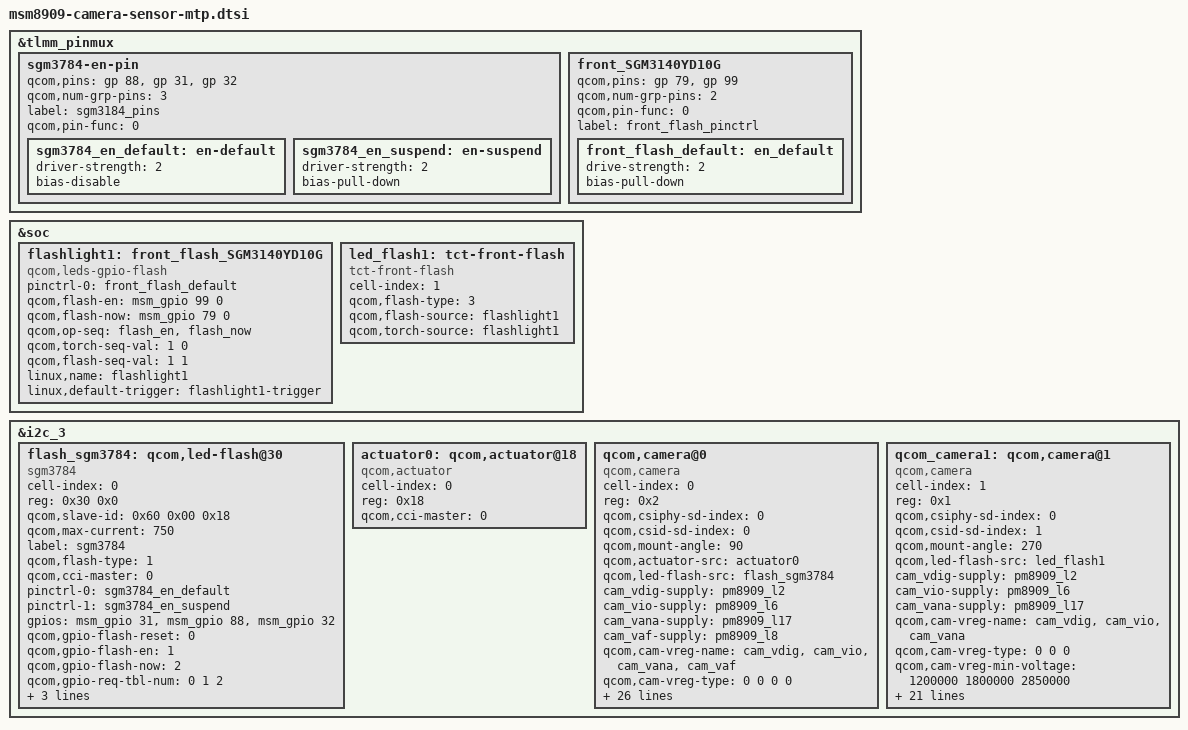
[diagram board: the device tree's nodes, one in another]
/*
 * Copyright (c) 2014-2015, The Linux Foundation. All rights reserved.
 *
 * This program is free software; you can redistribute it and/or modify
 * it under the terms of the GNU General Public License version 2 and
 * only version 2 as published by the Free Software Foundation.
 *
 * This program is distributed in the hope that it will be useful,
 * but WITHOUT ANY WARRANTY; without even the implied warranty of
 * MERCHANTABILITY or FITNESS FOR A PARTICULAR PURPOSE.  See the
 * GNU General Public License for more details.
 */
/*******************************************************************************

ChageList:

1.flashlight driver porting, by zhaohong.chen@tcl.com, 2016-01-18

*******************************************************************************/

&tlmm_pinmux {

	sgm3784-en-pin {
		qcom,pins = <&gp 88>, <&gp 31>, <&gp 32>;
		qcom,num-grp-pins = <3>;
		label = "sgm3184_pins";
		qcom,pin-func = <0>;

		sgm3784_en_default: en-default {
			driver-strength = <2>;
			bias-disable;
		};
		sgm3784_en_suspend: en-suspend {
			driver-strength = <2>;
			bias-pull-down;
		};
	};

	front_SGM3140YD10G {
		qcom,pins = <&gp 79>, <&gp 99>;
		qcom,num-grp-pins = <2>;
		qcom,pin-func = <0>;
		label = "front_flash_pinctrl";
		front_flash_default:en_default {
		drive-strength = <2>;
		bias-pull-down;
        };
    };
};

&soc {
	flashlight1:front_flash_SGM3140YD10G {
		compatible = "qcom,leds-gpio-flash";
		status = "okay";
		pinctrl-names = "flash_default";
		pinctrl-0 = <&front_flash_default>;
		qcom,flash-en = <&msm_gpio 99 0>;
		qcom,flash-now = <&msm_gpio 79 0>;
		qcom,op-seq = "flash_en", "flash_now";
		qcom,torch-seq-val = <1 0>;
		qcom,flash-seq-val = <1 1>;
		linux,name = "flashlight1";
		linux,default-trigger = "flashlight1-trigger";
	};

	led_flash1:tct-front-flash {
		cell-index = <1>;//front
		compatible = "tct-front-flash";
		qcom,flash-type = <3>;
		qcom,flash-source = <&flashlight1>;
		qcom,torch-source = <&flashlight1>;
	};
};

&i2c_3 {
	flash_sgm3784:qcom,led-flash@30 {
		cell-index = <0>;
		reg = <0x30 0x0>;
		qcom,slave-id = <0x60 0x00 0x18>; //0x60 >> 1 = 0x30 ,  real i2c addr
		compatible = "sgm3784";
		qcom,max-current = <750>; //determine current & the number of torch source
		label = "sgm3784";
		qcom,flash-type = <1>;
		qcom,cci-master = <0>;
		pinctrl-names = "cam_flash_default","cam_flash_suspend";
		pinctrl-0 = <&sgm3784_en_default>;
		pinctrl-1 = <&sgm3784_en_suspend>;
		gpios =		<&msm_gpio 31 0>,  //en
				<&msm_gpio 88 0>,  //strobe
				<&msm_gpio 32 0>;  //gpio
		qcom,gpio-flash-reset = <0>;
		qcom,gpio-flash-en = <1>;
		qcom,gpio-flash-now = <2>;
		qcom,gpio-req-tbl-num = <0 1 2>;
		qcom,gpio-req-tbl-flags = <0 0 0>;
		qcom,gpio-req-tbl-label = "FLASH_RST",
					  "FLASH_EN",
					  "FLASH_NOW";
	};
	
	actuator0: qcom,actuator@18 {
		cell-index = <0>;
		reg = <0x18>;
		compatible = "qcom,actuator";
		qcom,cci-master = <0>;
	};

	qcom,camera@0 {
		cell-index = <0>;
		compatible = "qcom,camera";
		reg = <0x2>;
		qcom,csiphy-sd-index = <0>;
		qcom,csid-sd-index = <0>;
		qcom,mount-angle = <90>;
		qcom,actuator-src = <&actuator0>;
		qcom,led-flash-src = <&flash_sgm3784>;
		cam_vdig-supply = <&pm8909_l2>;
		cam_vio-supply = <&pm8909_l6>;
		cam_vana-supply = <&pm8909_l17>;
		cam_vaf-supply = <&pm8909_l8>;
		qcom,cam-vreg-name = "cam_vdig", "cam_vio", "cam_vana", "cam_vaf";
		qcom,cam-vreg-type = <0 0 0 0>;
		qcom,cam-vreg-min-voltage = <1200000 1800000 2800000 2850000>;
		qcom,cam-vreg-max-voltage = <1200000 1800000 2850000 2900000>;
		qcom,cam-vreg-op-mode = <200000 200000 200000 100000>;
		pinctrl-names = "cam_default", "cam_suspend";
		pinctrl-0 = <&cam_sensor_mclk0_default &cam_sensor_rear_default>;
		pinctrl-1 = <&cam_sensor_mclk0_sleep &cam_sensor_rear_sleep>;
		gpios = <&msm_gpio 26 0>,
			<&msm_gpio 35 0>,
			<&msm_gpio 34 0>,
            <&msm_gpio 23 0>,
            <&msm_gpio 9 0>;
		qcom,gpio-reset = <1>;
		qcom,gpio-standby = <2>;
        qcom,gpio-af-pwdm = <3>;
        qcom,gpio-vana = <4>;
		qcom,gpio-req-tbl-num = <0 1 2 3 4>;
		qcom,gpio-req-tbl-flags = <1 0 0 0 0>;
		qcom,gpio-req-tbl-label = "CAMIF_MCLK",
			"CAM_RESET1",
			"CAM_STANDBY",
            "CAM_GPIO_AF",
            "CAM_GPIO_VANA";
		qcom,sensor-position = <0>;
		qcom,sensor-mode = <1>;
		qcom,cci-master = <0>;
		status = "ok";
		clocks = <&clock_gcc clk_mclk0_clk_src>,
				<&clock_gcc clk_gcc_camss_mclk0_clk>;
		clock-names = "cam_src_clk", "cam_clk";
	};

	qcom_camera1: qcom,camera@1 {
		cell-index = <1>;
		compatible = "qcom,camera";
		reg = <0x1>;
		qcom,csiphy-sd-index = <0>;
		qcom,csid-sd-index = <1>;
		qcom,mount-angle = <270>;
		qcom,led-flash-src = <&led_flash1>;
		cam_vdig-supply = <&pm8909_l2>;
		cam_vio-supply = <&pm8909_l6>;
		cam_vana-supply = <&pm8909_l17>;
		qcom,cam-vreg-name = "cam_vdig","cam_vio","cam_vana";
		qcom,cam-vreg-type = <0 0 0>;
		qcom,cam-vreg-min-voltage = <1200000 1800000 2850000>;
		qcom,cam-vreg-max-voltage = <1200000 1800000 2850000>;
		qcom,cam-vreg-op-mode = <1200000 1800000 1800000>;
		pinctrl-names = "cam_default", "cam_suspend";
		pinctrl-0 = <&cam_sensor_mclk1_default &cam_sensor_front_default>;
		pinctrl-1 = <&cam_sensor_mclk1_sleep &cam_sensor_front_sleep>;
		gpios = <&msm_gpio 27 0>,
			<&msm_gpio 28 0>,
			<&msm_gpio 33 0>,
			<&msm_gpio 9 0>;
		qcom,gpio-reset = <1>;
		qcom,gpio-standby = <2>;
		qcom,gpio-vana = <3>;
		qcom,gpio-req-tbl-num = <0 1 2 3>;
		qcom,gpio-req-tbl-flags = <1 0 0 0>;
		qcom,gpio-req-tbl-label = "CAMIF_MCLK",
					"CAM_RESET",
					"CAM_STANDBY",
					"CAM_GPIO_VANA";
		qcom,sensor-position = <1>;
		qcom,sensor-mode = <1>;
		qcom,cci-master = <0>;
		status = "ok";
		clocks = <&clock_gcc clk_mclk1_clk_src>,
				<&clock_gcc clk_gcc_camss_mclk1_clk>;
		clock-names = "cam_src_clk", "cam_clk";
	};
};
